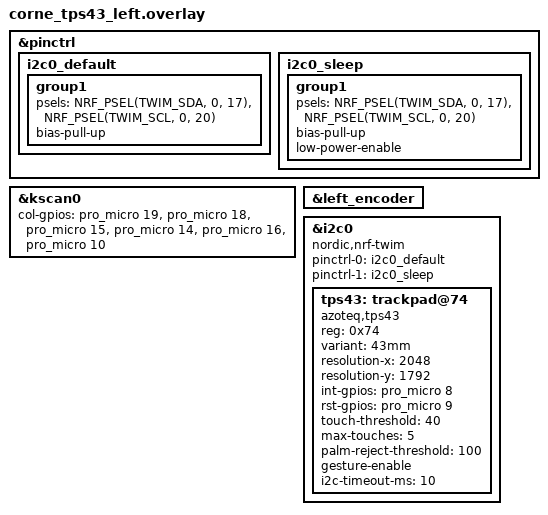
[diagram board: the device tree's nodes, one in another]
/*
 * Copyright (c) 2025 The ZMK Contributors
 *
 * SPDX-License-Identifier: MIT
 */

#include "corne_tps43.dtsi"

&pinctrl {
    i2c0_default: i2c0_default {
        group1 {
            psels = <NRF_PSEL(TWIM_SDA, 0, 17)>,
                    <NRF_PSEL(TWIM_SCL, 0, 20)>;
            bias-pull-up;
        };
    };

    i2c0_sleep: i2c0_sleep {
        group1 {
            psels = <NRF_PSEL(TWIM_SDA, 0, 17)>,
                    <NRF_PSEL(TWIM_SCL, 0, 20)>;
            bias-pull-up;
            low-power-enable;
        };
    };
};

&kscan0 {
    col-gpios
        = <&pro_micro 19 GPIO_ACTIVE_HIGH>
        , <&pro_micro 18 GPIO_ACTIVE_HIGH>
        , <&pro_micro 15 GPIO_ACTIVE_HIGH>
        , <&pro_micro 14 GPIO_ACTIVE_HIGH>
        , <&pro_micro 16 GPIO_ACTIVE_HIGH>
        , <&pro_micro 10 GPIO_ACTIVE_HIGH>
        ;
};

&left_encoder {
    status = "okay";
}; 

&i2c0 {
    compatible = "nordic,nrf-twim";
    status = "okay";
    pinctrl-0 = <&i2c0_default>;
    pinctrl-1 = <&i2c0_sleep>;
    pinctrl-names = "default", "sleep";

    tps43: trackpad@74 {
        compatible = "azoteq,tps43";
        reg = <0x74>;
        
        /* 43mm trackpad variant per datasheet */
        variant = "43mm";
        
        /* Resolution per TPS43 datasheet: 2048 x 1792 */
        resolution-x = <2048>;
        resolution-y = <1792>;
        
        /* GPIO connections for trackpad control */
        int-gpios = <&pro_micro 8 GPIO_ACTIVE_HIGH>;  /* INT pin for interrupt mode */
        rst-gpios = <&pro_micro 9 GPIO_ACTIVE_HIGH>;  /* RST pin for hardware reset */
        
        /* Touch sensitivity and behavior */
        touch-threshold = <40>;        /* Lower = more sensitive */
        max-touches = <5>;             /* 1-5 simultaneous touches */
        palm-reject-threshold = <100>; /* Ignore touches larger than this */
        
        /* Enable gesture recognition */
        gesture-enable;
        
        /* Communication timeout */
        i2c-timeout-ms = <10>;
    };
}; 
